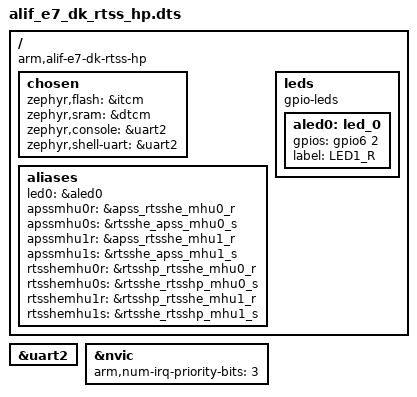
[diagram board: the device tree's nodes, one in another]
/* Copyright (c) 2024 Alif Semiconductor
 *
 * SPDX-License-Identifier: Apache-2.0
 */
/dts-v1/;

#include <alif/e7_rtss_common.dtsi>
#include <alif/ensemble_rtss_hp.dtsi>
#include <alif/ensemble-pinctrl.dtsi>

/ {
	compatible = "arm,alif-e7-dk-rtss-hp";
	#address-cells = <1>;
	#size-cells = <1>;

	chosen {
		zephyr,flash = &itcm;
		zephyr,sram = &dtcm;
		zephyr,console = &uart2;
		zephyr,shell-uart = &uart2;
	};

	aliases {
		led0 = &aled0;
		apssmhu0r = &apss_rtsshe_mhu0_r;
		apssmhu0s = &rtsshe_apss_mhu0_s;
		apssmhu1r = &apss_rtsshe_mhu1_r;
		apssmhu1s = &rtsshe_apss_mhu1_s;
		rtsshemhu0r = &rtsshp_rtsshe_mhu0_r;
		rtsshemhu0s = &rtsshe_rtsshp_mhu0_s;
		rtsshemhu1r = &rtsshp_rtsshe_mhu1_r;
		rtsshemhu1s = &rtsshe_rtsshp_mhu1_s;
	};

	leds {
		compatible = "gpio-leds";
		aled0: led_0 {
			gpios = <&gpio6 2 0>;
			label = "LED1_R";
		};
	};
};

&uart2 {
	status = "okay";
};
&nvic {
	arm,num-irq-priority-bits = <3>;
};
